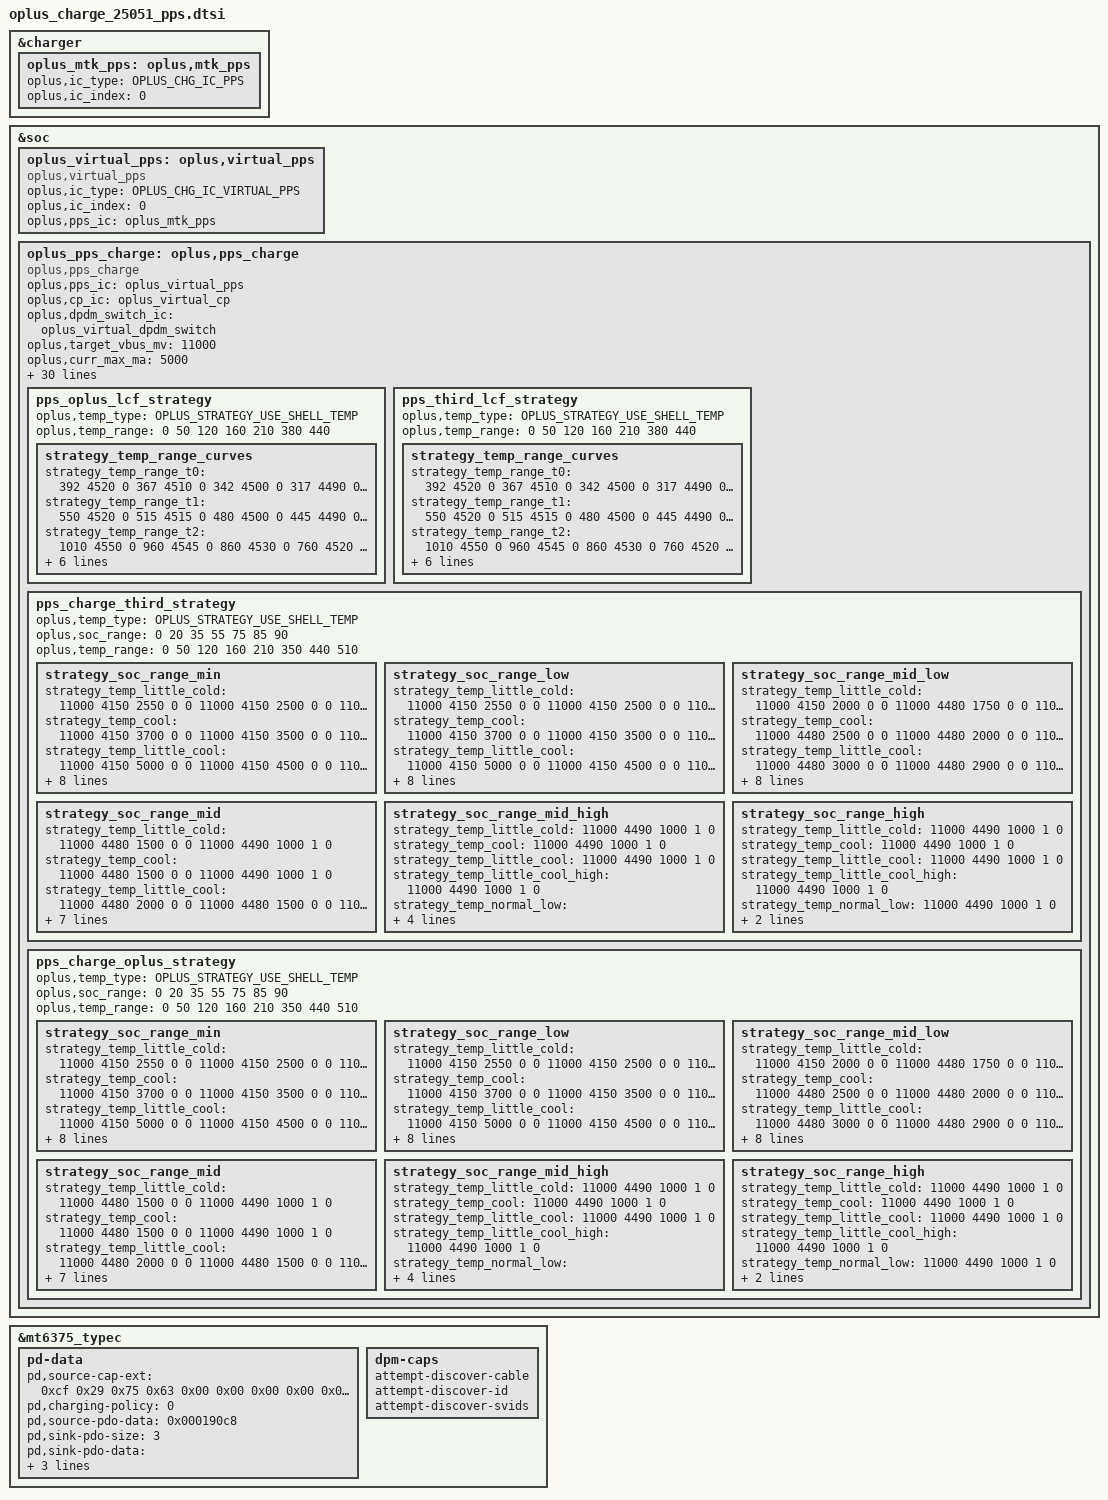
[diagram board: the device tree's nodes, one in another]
//ifdef OPLUS_FEATURE_CHG_BASIC
&charger {
	oplus_mtk_pps: oplus,mtk_pps {
		oplus,ic_type = <OPLUS_CHG_IC_PPS>;
		oplus,ic_index = <0>;
	};
};
&soc {
	oplus_virtual_pps: oplus,virtual_pps {
		compatible = "oplus,virtual_pps";

		oplus,ic_type = <OPLUS_CHG_IC_VIRTUAL_PPS>;
		oplus,ic_index = <0>;
		oplus,pps_ic = <&oplus_mtk_pps>;
	};
	oplus_pps_charge: oplus,pps_charge {
		compatible = "oplus,pps_charge";
		oplus,pps_ic = <&oplus_virtual_pps>;
		oplus,cp_ic = <&oplus_virtual_cp>;
		oplus,dpdm_switch_ic = <&oplus_virtual_dpdm_switch>;

		oplus,target_vbus_mv = <11000>;
		oplus,curr_max_ma = <5000>;
		oplus,curr_max_ma_percent = <2000 /* 75% ibus */
					     1000 /* 85% ibus */>;
		oplus,pps_warm_allow_vol = <4000>;
		oplus,pps_warm_allow_soc = <55>;
		oplus,pps_strategy_normal_current = <5000>;
		oplus,pps_over_high_or_low_current = <5000>;
		oplus,pps_timeout_third = <20005>;
		oplus,pps_timeout_oplus = <20005>;
		oplus,pps_ibat_over_third = <11400>;
		oplus,pps_ibat_over_oplus = <11400>;
		oplus,pps_full_cool_sw_vbat = <4490>;
		oplus,pps_full_normal_sw_vbat = <4490>;
		oplus,pps_full_normal_hw_vbat = <4540>;
		oplus,pps_full_ffc_vbat = <4510>;
		oplus,pps_full_warm_vbat = <4130>;
		oplus,pps_full_cool_sw_vbat_third = <4490>;
		oplus,pps_full_normal_sw_vbat_third= <4490>;
		oplus,pps_full_normal_hw_vbat_third = <4540>;
		oplus,pps_current_change_timeout = <100>;
		oplus,curve_strategy_name = "pps_ufcs_curve_v2";
		oplus,pps_strategy_batt_high_temp = <410 420 430 400 410 420>;
		oplus,pps_strategy_high_current = <5000 4000 2500 5000 5000 3000>;
		oplus,pps_little_cool_high_temp = <210>;
		oplus,pps_charge_strategy_soc = <0 20 35 55 75 85 85>;
		oplus,pps_charge_strategy_temp = <0 50 120 160 350 440 510>;

		oplus,plc_strategy-data = <&pps_simple_strategy>;
		oplus,plc_strategy-names = "default";

		pps_oplus_lcf_strategy {
			oplus,temp_type = <OPLUS_STRATEGY_USE_SHELL_TEMP>;
			oplus,temp_range = <0 50 120 160 210 380 440>;

			strategy_temp_range_curves {
				strategy_temp_range_t0 =	<392 4520 0
								 367 4510 0
								 342 4500 0
								 317 4490 0
								 292 4480 1>;
				strategy_temp_range_t1 =	<550 4520 0
								 515 4515 0
								 480 4500 0
								 445 4490 0
								 410 4480 1>;
				strategy_temp_range_t2 =	<1010 4550 0
								 960 4545 0
								 860 4530 0
								 760 4520 0
								 610 4510 1>;
				strategy_temp_range_t3 =	<1750 4550 0
								 1700 4545 0
								 1600 4530 0
								 1500 4520 0
								 1350 4510 1>;
				strategy_temp_range_t4 =	<1750 4550 0
								 1700 4545 0
								 1600 4530 0
								 1500 4520 0
								 1350 4510 1>;
				strategy_temp_range_t5 =	<2300 4535 0
								 2100 4525 0
								 1750 4500 0
								 1400 4480 0
								 1000 4460 1>;
			};
		};

		pps_third_lcf_strategy {
			oplus,temp_type = <OPLUS_STRATEGY_USE_SHELL_TEMP>;
			oplus,temp_range = <0 50 120 160 210 380 440>;

			strategy_temp_range_curves {
				strategy_temp_range_t0 =	<392 4520 0
								 367 4510 0
								 342 4500 0
								 317 4490 0
								 292 4480 1>;
				strategy_temp_range_t1 =	<550 4520 0
								 515 4515 0
								 480 4500 0
								 445 4490 0
								 410 4480 1>;
				strategy_temp_range_t2 =	<1010 4550 0
								 960 4545 0
								 860 4530 0
								 760 4520 0
								 610 4510 1>;
				strategy_temp_range_t3 =	<1750 4550 0
								 1700 4545 0
								 1600 4530 0
								 1500 4520 0
								 1350 4510 1>;
				strategy_temp_range_t4 =	<1750 4550 0
								 1700 4545 0
								 1600 4530 0
								 1500 4520 0
								 1350 4510 1>;
				strategy_temp_range_t5 =	<2300 4535 0
								 2100 4525 0
								 1750 4500 0
								 1400 4480 0
								 1000 4460 1>;
			};
		};

		pps_charge_third_strategy {
			oplus,temp_type = <OPLUS_STRATEGY_USE_SHELL_TEMP>;
			oplus,soc_range = <0 20 35 55 75 85 90>;
			oplus,temp_range = <0 50 120 160 210 350 440 510>;

			strategy_soc_range_min { /* 0-20 */
				strategy_temp_little_cold =	<11000 4150 2550 0 0 /* 0-5 */
								11000 4150 2500 0 0
								11000 4150 2000 0 0
								11000 4480 1750 0 0
								11000 4480 1500 0 0
								11000 4490 1000 1 0>;
				strategy_temp_cool =		<11000 4150 3700 0 0 /* 5-12 */
								11000 4150 3500 0 0
								11000 4150 3000 0 0
								11000 4480 2550 0 0
								11000 4480 2500 0 0
								11000 4480 2000 0 0
								11000 4480 1500 0 0
								11000 4490 1000 1 0>;
				strategy_temp_little_cool =	<11000 4150 5000 0 0 /* 12-16 */
								11000 4150 4500 0 0
								11000 4480 4450 0 0
								11000 4480 4000 0 0
								11000 4480 3500 0 0
								11000 4480 3000 0 0
								11000 4480 2900 0 0
								11000 4480 2500 0 0
								11000 4480 2000 0 0
								11000 4480 1500 0 0
								11000 4490 1000 1 0>;
				strategy_temp_little_cool_high = <11000 4230 5000 0 0 /* 16-21 */
								11000 4230 4500 0 0
								11000 4480 4450 0 0
								11000 4480 4000 0 0
								11000 4480 3500 0 0
								11000 4480 3000 0 0
								11000 4480 2900 0 0
								11000 4480 2500 0 0
								11000 4480 2000 0 0
								11000 4480 1500 0 0
								11000 4490 1000 1 0>;
				strategy_temp_normal_low =	<11000 4230 5000 0 0 /* 21-35 */
								11000 4230 4500 0 0
								11000 4480 4450 0 0
								11000 4480 4000 0 0
								11000 4480 3500 0 0
								11000 4480 3000 0 0
								11000 4480 2900 0 0
								11000 4480 2500 0 0
								11000 4480 2000 0 0
								11000 4480 1500 0 0
								11000 4490 1000 1 0>;
				strategy_temp_normal_high =	<11000 4230 5000 0 0 /* 35-44 */
								11000 4230 4500 0 0
								11000 4460 4450 0 0
								11000 4460 4000 0 0
								11000 4460 3500 0 0
								11000 4460 3000 0 0
								11000 4460 2900 0 0
								11000 4460 2500 0 0
								11000 4460 2000 0 0
								11000 4460 1500 0 0
								11000 4470 1000 1 0>;
				strategy_temp_warm =		<11000 4120 2000 0 0 /* 44-51 */
								11000 4120 1500 0 0
								11000 4130 1000 1 0>;
			};
			strategy_soc_range_low { /* 21-35 */
				strategy_temp_little_cold =	<11000 4150 2550 0 0 /* 0-5 */
								11000 4150 2500 0 0
								11000 4150 2000 0 0
								11000 4480 1750 0 0
								11000 4480 1500 0 0
								11000 4490 1000 1 0>;
				strategy_temp_cool =		<11000 4150 3700 0 0 /* 5-12 */
								11000 4150 3500 0 0
								11000 4150 3000 0 0
								11000 4480 2550 0 0
								11000 4480 2500 0 0
								11000 4480 2000 0 0
								11000 4480 1500 0 0
								11000 4490 1000 1 0>;
				strategy_temp_little_cool =	<11000 4150 5000 0 0 /* 12-16 */
								11000 4150 4500 0 0
								11000 4480 4450 0 0
								11000 4480 4000 0 0
								11000 4480 3500 0 0
								11000 4480 3000 0 0
								11000 4480 2900 0 0
								11000 4480 2500 0 0
								11000 4480 2000 0 0
								11000 4480 1500 0 0
								11000 4490 1000 1 0>;
				strategy_temp_little_cool_high = <11000 4230 5000 0 0 /* 16-21 */
								11000 4230 4500 0 0
								11000 4480 4450 0 0
								11000 4480 4000 0 0
								11000 4480 3500 0 0
								11000 4480 3000 0 0
								11000 4480 2900 0 0
								11000 4480 2500 0 0
								11000 4480 2000 0 0
								11000 4480 1500 0 0
								11000 4490 1000 1 0>;
				strategy_temp_normal_low =	<11000 4230 5000 0 0 /* 21-35 */
								11000 4230 4500 0 0
								11000 4480 4450 0 0
								11000 4480 4000 0 0
								11000 4480 3500 0 0
								11000 4480 3000 0 0
								11000 4480 2900 0 0
								11000 4480 2500 0 0
								11000 4480 2000 0 0
								11000 4480 1500 0 0
								11000 4490 1000 1 0>;
				strategy_temp_normal_high =	<11000 4230 5000 0 0 /* 35-44 */
								11000 4230 4500 0 0
								11000 4460 4450 0 0
								11000 4460 4000 0 0
								11000 4460 3500 0 0
								11000 4460 3000 0 0
								11000 4460 2900 0 0
								11000 4460 2500 0 0
								11000 4460 2000 0 0
								11000 4460 1500 0 0
								11000 4470 1000 1 0>;
				strategy_temp_warm =		<11000 4120 2000 0 0 /* 44-51 */
								11000 4120 1500 0 0
								11000 4130 1000 1 0>;
			};
			strategy_soc_range_mid_low { /* 36-55 */
				strategy_temp_little_cold =	<11000 4150 2000 0 0 /* 0-5 */
								11000 4480 1750 0 0
								11000 4480 1500 0 0
								11000 4490 1000 1 0>;
				strategy_temp_cool =		<11000 4480 2500 0 0 /* 5-12 */
								11000 4480 2000 0 0
								11000 4480 1500 0 0
								11000 4490 1000 1 0>;
				strategy_temp_little_cool =	<11000 4480 3000 0 0 /* 12-16 */
								11000 4480 2900 0 0
								11000 4480 2500 0 0
								11000 4480 2000 0 0
								11000 4480 1500 0 0
								11000 4490 1000 1 0>;
				strategy_temp_little_cool_high = <11000 4480 3000 0 0 /* 16-21 */
								11000 4480 2900 0 0
								11000 4480 2500 0 0
								11000 4480 2000 0 0
								11000 4480 1500 0 0
								11000 4490 1000 1 0>;
				strategy_temp_normal_low =	<11000 4230 5000 0 0 /* 21-35 */
								11000 4230 4500 0 0
								11000 4480 4450 0 0
								11000 4480 4000 0 0
								11000 4480 3500 0 0
								11000 4480 3000 0 0
								11000 4480 2900 0 0
								11000 4480 2500 0 0
								11000 4480 2000 0 0
								11000 4480 1500 0 0
								11000 4490 1000 1 0>;
				strategy_temp_normal_high =	<11000 4230 5000 0 0 /* 35-44 */
								11000 4230 4500 0 0
								11000 4460 4450 0 0
								11000 4460 4000 0 0
								11000 4460 3500 0 0
								11000 4460 3000 0 0
								11000 4460 2900 0 0
								11000 4460 2500 0 0
								11000 4460 2000 0 0
								11000 4460 1500 0 0
								11000 4470 1000 1 0>;
				strategy_temp_warm =		<11000 4120 2000 0 0 /* 44-51 */
								11000 4120 1500 0 0
								11000 4130 1000 1 0>;
			};
			strategy_soc_range_mid { /* 56-75 */
				strategy_temp_little_cold =	<11000 4480 1500 0 0 /* 0-5 */
								11000 4490 1000 1 0>;
				strategy_temp_cool =		<11000 4480 1500 0 0 /* 5-12 */
								11000 4490 1000 1 0>;
				strategy_temp_little_cool =	<11000 4480 2000 0 0 /* 12-16 */
								11000 4480 1500 0 0
								11000 4490 1000 1 0>;
				strategy_temp_little_cool_high = <11000 4480 2000 0 0 /* 16-21 */
								11000 4480 1500 0 0
								11000 4490 1000 1 0>;
				strategy_temp_normal_low =	<11000 4480 2000 0 0 /* 21-35 */
								11000 4480 1500 0 0
								11000 4490 1000 1 0>;
				strategy_temp_normal_high =	<11000 4460 2500 0 0 /* 35-44 */
								11000 4460 2000 0 0
								11000 4460 1500 0 0
								11000 4470 1000 1 0>;
				strategy_temp_warm =		<11000 4130 1000 1 0>; /* 44-51 */
			};
			strategy_soc_range_mid_high { /* 76-85 */
				strategy_temp_little_cold =	<11000 4490 1000 1 0>; /* 0-5 */
				strategy_temp_cool =		<11000 4490 1000 1 0>; /* 5-12 */
				strategy_temp_little_cool =	<11000 4490 1000 1 0>; /* 12-16 */
				strategy_temp_little_cool_high = <11000 4490 1000 1 0>; /* 16-21 */
				strategy_temp_normal_low =	<11000 4480 1500 0 0 /* 21-35 */
								11000 4490 1000 1 0>;
				strategy_temp_normal_high =	<11000 4460 1500 0 0 /* 35-44 */
								11000 4470 1000 1 0>;
				strategy_temp_warm =		<11000 4130 1000 1 0>; /* 44-51 */
			};
			strategy_soc_range_high { /* 86-90 */
				strategy_temp_little_cold =	<11000 4490 1000 1 0>; /* 0-5 */
				strategy_temp_cool =		<11000 4490 1000 1 0>; /* 5-12 */
				strategy_temp_little_cool =	<11000 4490 1000 1 0>; /* 12-16 */
				strategy_temp_little_cool_high = <11000 4490 1000 1 0>; /* 16-21 */
				strategy_temp_normal_low =	<11000 4490 1000 1 0>; /* 21-35 */
				strategy_temp_normal_high =	<11000 4470 1000 1 0>;/* 35-44 */
				strategy_temp_warm =		<11000 4130 1000 1 0>; /* 44-51 */
			};
		};

		pps_charge_oplus_strategy {
			oplus,temp_type = <OPLUS_STRATEGY_USE_SHELL_TEMP>;
			oplus,soc_range = <0 20 35 55 75 85 90>;
			oplus,temp_range = <0 50 120 160 210 350 440 510>;

			strategy_soc_range_min { /* 0-20 */
				strategy_temp_little_cold =	<11000 4150 2550 0 0 /* 0-5 */
								11000 4150 2500 0 0
								11000 4150 2000 0 0
								11000 4480 1750 0 0
								11000 4480 1500 0 0
								11000 4490 1000 1 0>;
				strategy_temp_cool =		<11000 4150 3700 0 0 /* 5-12 */
								11000 4150 3500 0 0
								11000 4150 3000 0 0
								11000 4480 2550 0 0
								11000 4480 2500 0 0
								11000 4480 2000 0 0
								11000 4480 1500 0 0
								11000 4490 1000 1 0>;
				strategy_temp_little_cool =	<11000 4150 5000 0 0 /* 12-16 */
								11000 4150 4500 0 0
								11000 4480 4450 0 0
								11000 4480 4000 0 0
								11000 4480 3500 0 0
								11000 4480 3000 0 0
								11000 4480 2900 0 0
								11000 4480 2500 0 0
								11000 4480 2000 0 0
								11000 4480 1500 0 0
								11000 4490 1000 1 0>;
				strategy_temp_little_cool_high = <11000 4230 5000 0 0 /* 16-21 */
								11000 4230 4500 0 0
								11000 4480 4450 0 0
								11000 4480 4000 0 0
								11000 4480 3500 0 0
								11000 4480 3000 0 0
								11000 4480 2900 0 0
								11000 4480 2500 0 0
								11000 4480 2000 0 0
								11000 4480 1500 0 0
								11000 4490 1000 1 0>;
				strategy_temp_normal_low =	<11000 4230 5000 0 0 /* 21-35 */
								11000 4230 4500 0 0
								11000 4480 4450 0 0
								11000 4480 4000 0 0
								11000 4480 3500 0 0
								11000 4480 3000 0 0
								11000 4480 2900 0 0
								11000 4480 2500 0 0
								11000 4480 2000 0 0
								11000 4480 1500 0 0
								11000 4490 1000 1 0>;
				strategy_temp_normal_high =	<11000 4230 5000 0 0 /* 35-44 */
								11000 4230 4500 0 0
								11000 4460 4450 0 0
								11000 4460 4000 0 0
								11000 4460 3500 0 0
								11000 4460 3000 0 0
								11000 4460 2900 0 0
								11000 4460 2500 0 0
								11000 4460 2000 0 0
								11000 4460 1500 0 0
								11000 4470 1000 1 0>;
				strategy_temp_warm =		<11000 4120 2000 0 0 /* 44-51 */
								11000 4120 1500 0 0
								11000 4130 1000 1 0>;
			};
			strategy_soc_range_low { /* 21-35 */
				strategy_temp_little_cold =	<11000 4150 2550 0 0 /* 0-5 */
								11000 4150 2500 0 0
								11000 4150 2000 0 0
								11000 4480 1750 0 0
								11000 4480 1500 0 0
								11000 4490 1000 1 0>;
				strategy_temp_cool =		<11000 4150 3700 0 0 /* 5-12 */
								11000 4150 3500 0 0
								11000 4150 3000 0 0
								11000 4480 2550 0 0
								11000 4480 2500 0 0
								11000 4480 2000 0 0
								11000 4480 1500 0 0
								11000 4490 1000 1 0>;
				strategy_temp_little_cool =	<11000 4150 5000 0 0 /* 12-16 */
								11000 4150 4500 0 0
								11000 4480 4450 0 0
								11000 4480 4000 0 0
								11000 4480 3500 0 0
								11000 4480 3000 0 0
								11000 4480 2900 0 0
								11000 4480 2500 0 0
								11000 4480 2000 0 0
								11000 4480 1500 0 0
								11000 4490 1000 1 0>;
				strategy_temp_little_cool_high = <11000 4230 5000 0 0 /* 16-21 */
								11000 4230 4500 0 0
								11000 4480 4450 0 0
								11000 4480 4000 0 0
								11000 4480 3500 0 0
								11000 4480 3000 0 0
								11000 4480 2900 0 0
								11000 4480 2500 0 0
								11000 4480 2000 0 0
								11000 4480 1500 0 0
								11000 4490 1000 1 0>;
				strategy_temp_normal_low =	<11000 4230 5000 0 0 /* 21-35 */
								11000 4230 4500 0 0
								11000 4480 4450 0 0
								11000 4480 4000 0 0
								11000 4480 3500 0 0
								11000 4480 3000 0 0
								11000 4480 2900 0 0
								11000 4480 2500 0 0
								11000 4480 2000 0 0
								11000 4480 1500 0 0
								11000 4490 1000 1 0>;
				strategy_temp_normal_high =	<11000 4230 5000 0 0 /* 35-44 */
								11000 4230 4500 0 0
								11000 4460 4450 0 0
								11000 4460 4000 0 0
								11000 4460 3500 0 0
								11000 4460 3000 0 0
								11000 4460 2900 0 0
								11000 4460 2500 0 0
								11000 4460 2000 0 0
								11000 4460 1500 0 0
								11000 4470 1000 1 0>;
				strategy_temp_warm =		<11000 4120 2000 0 0 /* 44-51 */
								11000 4120 1500 0 0
								11000 4130 1000 1 0>;
			};
			strategy_soc_range_mid_low { /* 36-55 */
				strategy_temp_little_cold =	<11000 4150 2000 0 0 /* 0-5 */
								11000 4480 1750 0 0
								11000 4480 1500 0 0
								11000 4490 1000 1 0>;
				strategy_temp_cool =		<11000 4480 2500 0 0 /* 5-12 */
								11000 4480 2000 0 0
								11000 4480 1500 0 0
								11000 4490 1000 1 0>;
				strategy_temp_little_cool =	<11000 4480 3000 0 0 /* 12-16 */
								11000 4480 2900 0 0
								11000 4480 2500 0 0
								11000 4480 2000 0 0
								11000 4480 1500 0 0
								11000 4490 1000 1 0>;
				strategy_temp_little_cool_high = <11000 4480 3000 0 0 /* 16-21 */
								11000 4480 2900 0 0
								11000 4480 2500 0 0
								11000 4480 2000 0 0
								11000 4480 1500 0 0
								11000 4490 1000 1 0>;
				strategy_temp_normal_low =	<11000 4230 5000 0 0 /* 21-35 */
								11000 4230 4500 0 0
								11000 4480 4450 0 0
								11000 4480 4000 0 0
								11000 4480 3500 0 0
								11000 4480 3000 0 0
								11000 4480 2900 0 0
								11000 4480 2500 0 0
								11000 4480 2000 0 0
								11000 4480 1500 0 0
								11000 4490 1000 1 0>;
				strategy_temp_normal_high =	<11000 4230 5000 0 0 /* 35-44 */
								11000 4230 4500 0 0
								11000 4460 4450 0 0
								11000 4460 4000 0 0
								11000 4460 3500 0 0
								11000 4460 3000 0 0
								11000 4460 2900 0 0
								11000 4460 2500 0 0
								11000 4460 2000 0 0
								11000 4460 1500 0 0
								11000 4470 1000 1 0>;
				strategy_temp_warm =		<11000 4120 2000 0 0 /* 44-51 */
								11000 4120 1500 0 0
								11000 4130 1000 1 0>;
			};
			strategy_soc_range_mid { /* 56-75 */
				strategy_temp_little_cold =	<11000 4480 1500 0 0 /* 0-5 */
								11000 4490 1000 1 0>;
				strategy_temp_cool =		<11000 4480 1500 0 0 /* 5-12 */
								11000 4490 1000 1 0>;
				strategy_temp_little_cool =	<11000 4480 2000 0 0 /* 12-16 */
								11000 4480 1500 0 0
								11000 4490 1000 1 0>;
				strategy_temp_little_cool_high = <11000 4480 2000 0 0 /* 16-21 */
								11000 4480 1500 0 0
								11000 4490 1000 1 0>;
				strategy_temp_normal_low =	<11000 4480 2000 0 0 /* 21-35 */
								11000 4480 1500 0 0
								11000 4490 1000 1 0>;
				strategy_temp_normal_high =	<11000 4460 2500 0 0 /* 35-44 */
								11000 4460 2000 0 0
								11000 4460 1500 0 0
								11000 4470 1000 1 0>;
				strategy_temp_warm =		<11000 4130 1000 1 0>; /* 44-51 */
			};
			strategy_soc_range_mid_high { /* 76-85 */
				strategy_temp_little_cold =	<11000 4490 1000 1 0>; /* 0-5 */
				strategy_temp_cool =		<11000 4490 1000 1 0>; /* 5-12 */
				strategy_temp_little_cool =	<11000 4490 1000 1 0>; /* 12-16 */
				strategy_temp_little_cool_high = <11000 4490 1000 1 0>; /* 16-21 */
				strategy_temp_normal_low =	<11000 4480 1500 0 0 /* 21-35 */
								11000 4490 1000 1 0>;
				strategy_temp_normal_high =	<11000 4460 1500 0 0 /* 35-44 */
								11000 4470 1000 1 0>;
				strategy_temp_warm =		<11000 4130 1000 1 0>; /* 44-51 */
			};
			strategy_soc_range_high { /* 86-90 */
				strategy_temp_little_cold =	<11000 4490 1000 1 0>; /* 0-5 */
				strategy_temp_cool =		<11000 4490 1000 1 0>; /* 5-12 */
				strategy_temp_little_cool =	<11000 4490 1000 1 0>; /* 12-16 */
				strategy_temp_little_cool_high = <11000 4490 1000 1 0>; /* 16-21 */
				strategy_temp_normal_low =	<11000 4490 1000 1 0>; /* 21-35 */
				strategy_temp_normal_high =	<11000 4470 1000 1 0>;/* 35-44 */
				strategy_temp_warm =		<11000 4130 1000 1 0>; /* 44-51 */
			};
		};
	};
};

/* for pd common charger */
&mt6375_typec {
	pd-data {
			pd,source-cap-ext = /bits/ 8 <0xcf 0x29 0x75 0x63
							      0x00 0x00 0x00 0x00
							      0x00 0x00 0x00 0x00
							      0x00 0x00 0x00 0x00
							      0x00 0x00 0x00 0x00
							      0x00 0x00 0x01 0x05
							      0x00>;

			pd,charging-policy = <0>;

			pd,source-pdo-data = <0x000190c8>;/* Fixed, 5000mV, 2000mA*/

			/*0x000190c8: Fixed, 5000mV, 2000mA*/
			/*0x0002d096: Fixed, 9000mV, 1500mA*/
			/*0xc0dc1e64: apdo, min 3000mV, max 11000mV, 5000mA*/
			pd,sink-pdo-size = <3>;
			pd,sink-pdo-data = <0x000190c8 0x0002d096 0xc0dc1e64>;

			/* No DP, host + device */
			pd,id-vdo-data = <0xd14029cf 0x0 0x63750000
						  0x61000000 0x0 0x41000000>;
	};

	dpm-caps {
			// attempt-enter-dp-mode;
			attempt-discover-cable;
			attempt-discover-id;
			attempt-discover-svids;
	};
};

//#endif OPLUS_FEATURE_CHG_BASIC
